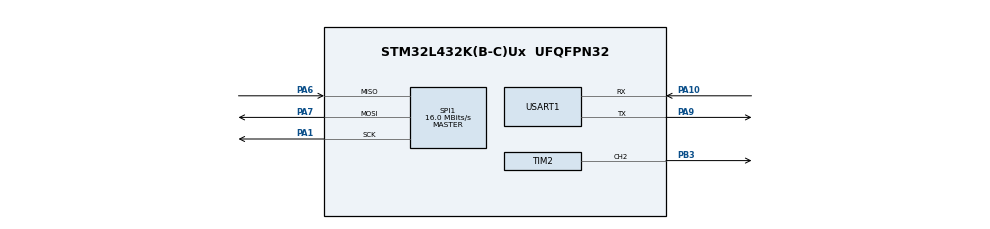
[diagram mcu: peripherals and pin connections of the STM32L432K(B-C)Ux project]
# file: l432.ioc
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Mcu.Family=STM32L4
Mcu.Name=STM32L432K(B-C)Ux
Mcu.Package=UFQFPN32
NVIC.PriorityGroup=NVIC_PRIORITYGROUP_4
NVIC.TIM1_BRK_TIM15_IRQn=true\:0\:0\:false\:false\:true\:true\:true\:true
PA0.GPIO_Label=MCO [High speed clock in]
PA0.Mode=HSE-External-Clock-Source-for-LittleOrca
PA0.Signal=RCC_CK_IN
PA1.Mode=Full_Duplex_Master
PA1.Signal=SPI1_SCK
PA10.Mode=Asynchronous
PA10.Signal=USART1_RX
PA13\ (JTMS-SWDIO).GPIO_Label=SWDIO
PA13\ (JTMS-SWDIO).Mode=Serial_Wire
PA13\ (JTMS-SWDIO).Signal=SYS_JTMS-SWDIO
PA14\ (JTCK-SWCLK).GPIO_Label=SWCLK
PA14\ (JTCK-SWCLK).Mode=Serial_Wire
PA14\ (JTCK-SWCLK).Signal=SYS_JTCK-SWCLK
PA15\ (JTDI).GPIO_Label=VCP_RX
PA15\ (JTDI).Signal=USART2_RX
PA6.Mode=Full_Duplex_Master
PA6.Signal=SPI1_MISO
PA7.Mode=Full_Duplex_Master
PA7.Signal=SPI1_MOSI
PA9.Mode=Asynchronous
PA9.Signal=USART1_TX
PB3\ (JTDO-TRACESWO).Signal=S_TIM2_CH2
PC14-OSC32_IN\ (PC14).Mode=LSE-External-Oscillator
PC14-OSC32_IN\ (PC14).Signal=RCC_OSC32_IN
PC15-OSC32_OUT\ (PC15).Mode=LSE-External-Oscillator
PC15-OSC32_OUT\ (PC15).Signal=RCC_OSC32_OUT
ProjectManager.HeapSize=0x200
ProjectManager.StackSize=0x400
ProjectManager.TargetToolchain=STM32CubeIDE
RCC.AHBFreq_Value=32000000
RCC.APB1Freq_Value=32000000
RCC.APB1TimFreq_Value=32000000
RCC.APB2Freq_Value=32000000
RCC.APB2TimFreq_Value=32000000
RCC.CortexFreq_Value=32000000
RCC.HCLKFreq_Value=32000000
RCC.HSE_VALUE=8000000
RCC.HSI16_VALUE=16000000
RCC.HSI48_VALUE=48000000
RCC.HSI_VALUE=16000000
RCC.MSI_VALUE=4000000
RCC.PLLMUL=RCC_PLLMUL_4
RCC.PLLN=16
RCC.SYSCLKFreq_VALUE=32000000
RCC.SYSCLKSource=RCC_SYSCLKSOURCE_PLLCLK
RCC.VCOOutputFreq_Value=64000000
SH.S_TIM2_CH2.0=TIM2_CH2,PWM Generation2 CH2
SPI1.CalculateBaudRate=16.0 MBits/s
SPI1.Direction=SPI_DIRECTION_2LINES
SPI1.Mode=SPI_MODE_MASTER
SPI1.VirtualType=VM_MASTER
TIM15.Period=32000
TIM2.Channel-PWM\ Generation2\ CH2=TIM_CHANNEL_2
TIM2.Period=255
TIM2.Prescaler=124
USART1.VirtualMode-Asynchronous=VM_ASYNC
VP_TIM15_VS_ClockSourceINT.Mode=Internal
VP_TIM2_VS_ClockSourceINT.Mode=Internal
board=NUCLEO-L432KC

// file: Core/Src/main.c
/* USER CODE BEGIN Header */
/**
  ******************************************************************************
  * @file           : main.c
  * @brief          : Main program body
  ******************************************************************************
  * @attention
  *
  * Copyright (c) 2024 STMicroelectronics.
  * All rights reserved.
  *
  * This software is licensed under terms that can be found in the LICENSE file
  * in the root directory of this software component.
  * If no LICENSE file comes with this software, it is provided AS-IS.
  *
  ******************************************************************************
  */
/* USER CODE END Header */
#include "main.h"
#include "spi.h"
#include "tim.h"
#include "usart.h"
#include "gpio.h"

/* USER CODE BEGIN Includes */
#include "TimeBase.h"
/* USER CODE END Includes */

void SystemClock_Config(void);

int main(void)
{

  /* MCU Configuration--------------------------------------------------------*/

  /* Reset of all peripherals, Initializes the Flash interface and the Systick. */
  LL_APB2_GRP1_EnableClock(LL_APB2_GRP1_PERIPH_SYSCFG);
  LL_APB1_GRP1_EnableClock(LL_APB1_GRP1_PERIPH_PWR);

  /* System interrupt init*/
  NVIC_SetPriorityGrouping(NVIC_PRIORITYGROUP_4);

  /* Configure the system clock */
  SystemClock_Config();

  /* Initialize all configured peripherals */
  MX_GPIO_Init();
  MX_TIM2_Init();
  MX_SPI1_Init();
  MX_USART1_UART_Init();
  MX_TIM15_Init();
  /* USER CODE BEGIN 2 */

  LedStart(); // Démarre le timer pour activer la PWM
  TimeBaseStartIT();
  /* USER CODE END 2 */

  /* Infinite loop */
  /* USER CODE BEGIN WHILE */
  while (1)
  {
   // Incrémente et décrémente la luminosité de la LED à chaque itération
   //LedPulse();
   //HAL_Delay(1); // Ajouter un petit délai pour contrôler la fréquence de changement de luminosité

    /* USER CODE END WHILE */

  }
}

void SystemClock_Config(void)
{
  LL_FLASH_SetLatency(LL_FLASH_LATENCY_1);
  while(LL_FLASH_GetLatency()!= LL_FLASH_LATENCY_1)
  {
  }
  LL_PWR_SetRegulVoltageScaling(LL_PWR_REGU_VOLTAGE_SCALE1);
  while (LL_PWR_IsActiveFlag_VOS() != 0)
  {
  }
  LL_RCC_MSI_Enable();

   /* Wait till MSI is ready */
  while(LL_RCC_MSI_IsReady() != 1)
  {

  }
  LL_RCC_MSI_EnableRangeSelection();
  LL_RCC_MSI_SetRange(LL_RCC_MSIRANGE_6);
  LL_RCC_MSI_SetCalibTrimming(0);
  LL_PWR_EnableBkUpAccess();
  LL_RCC_LSE_SetDriveCapability(LL_RCC_LSEDRIVE_LOW);
  LL_RCC_LSE_Enable();

   /* Wait till LSE is ready */
  while(LL_RCC_LSE_IsReady() != 1)
  {

  }
  LL_RCC_MSI_EnablePLLMode();
  LL_RCC_PLL_ConfigDomain_SYS(LL_RCC_PLLSOURCE_MSI, LL_RCC_PLLM_DIV_1, 16, LL_RCC_PLLR_DIV_2);
  LL_RCC_PLL_EnableDomain_SYS();
  LL_RCC_PLL_Enable();

   /* Wait till PLL is ready */
  while(LL_RCC_PLL_IsReady() != 1)
  {

  }
  LL_RCC_SetSysClkSource(LL_RCC_SYS_CLKSOURCE_PLL);

   /* Wait till System clock is ready */
  while(LL_RCC_GetSysClkSource() != LL_RCC_SYS_CLKSOURCE_STATUS_PLL)
  {

  }
  LL_RCC_SetAHBPrescaler(LL_RCC_SYSCLK_DIV_1);
  LL_RCC_SetAPB1Prescaler(LL_RCC_APB1_DIV_1);
  LL_RCC_SetAPB2Prescaler(LL_RCC_APB2_DIV_1);

  LL_Init1msTick(32000000);

  LL_SetSystemCoreClock(32000000);
}

void Error_Handler(void)
{
  __disable_irq();
  while (1)
  {
  }
}
